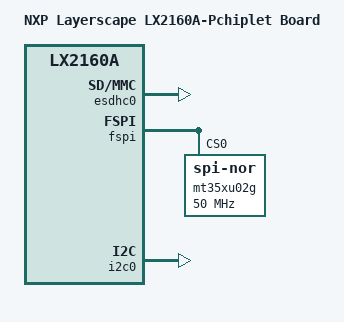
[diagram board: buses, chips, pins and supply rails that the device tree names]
// SPDX-License-Identifier: GPL-2.0+ OR X11
/*
 * NXP LX2160A-Pchiplet device tree source
 *
 * Author: Yanan Yang <yanan.yang@nxp.com>
 *
 * Copyright 2020 NXP
 *
 */

/dts-v1/;

#include "fsl-lx2160a.dtsi"

/ {
	model = "NXP Layerscape LX2160A-Pchiplet Board";
	compatible = "fsl,lx2160apchiplet", "fsl,lx2160a";
	aliases {
		spi0 = &fspi;
	};
};

&esdhc0 {
	status = "okay";
};

&fspi {
	status = "okay";

	mt35xu02g: flash@0 {
		#address-cells = <1>;
		#size-cells = <1>;
		compatible = "jedec,spi-nor";
		spi-max-frequency = <50000000>;
		reg = <0>;
	};

};

&i2c0 {
	status = "okay";
	u-boot,dm-pre-reloc;
};
